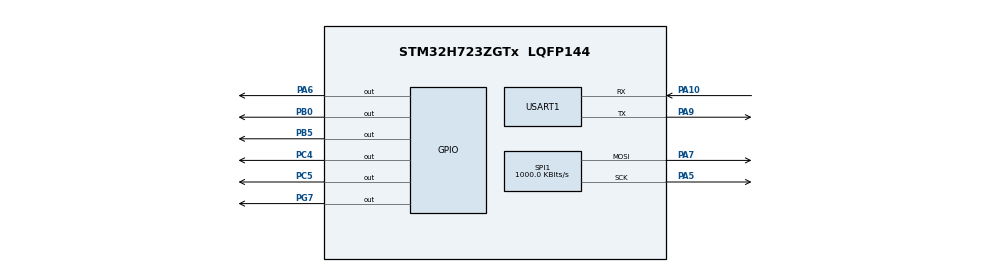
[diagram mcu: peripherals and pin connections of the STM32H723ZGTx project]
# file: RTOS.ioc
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Dma.Request0=SPI1_TX
Dma.SPI1_TX.0.Direction=DMA_MEMORY_TO_PERIPH
Dma.SPI1_TX.0.EventEnable=DISABLE
Dma.SPI1_TX.0.FIFOMode=DMA_FIFOMODE_DISABLE
Dma.SPI1_TX.0.Instance=DMA1_Stream0
Dma.SPI1_TX.0.MemDataAlignment=DMA_MDATAALIGN_BYTE
Dma.SPI1_TX.0.MemInc=DMA_MINC_ENABLE
Dma.SPI1_TX.0.Mode=DMA_NORMAL
Dma.SPI1_TX.0.PeriphDataAlignment=DMA_PDATAALIGN_BYTE
Dma.SPI1_TX.0.PeriphInc=DMA_PINC_DISABLE
Dma.SPI1_TX.0.Polarity=HAL_DMAMUX_REQ_GEN_RISING
Dma.SPI1_TX.0.Priority=DMA_PRIORITY_HIGH
Dma.SPI1_TX.0.RequestNumber=1
Dma.SPI1_TX.0.SignalID=NONE
Dma.SPI1_TX.0.SyncEnable=DISABLE
Dma.SPI1_TX.0.SyncPolarity=HAL_DMAMUX_SYNC_NO_EVENT
Dma.SPI1_TX.0.SyncRequestNumber=1
Dma.SPI1_TX.0.SyncSignalID=NONE
Mcu.Family=STM32H7
Mcu.Name=STM32H723ZGTx
Mcu.Package=LQFP144
NVIC.DMA1_Stream0_IRQn=true\:3\:0\:true\:false\:true\:true\:true\:true
NVIC.PriorityGroup=NVIC_PRIORITYGROUP_4
NVIC.SPI1_IRQn=true\:3\:0\:true\:false\:true\:false\:true\:true
NVIC.TIM7_IRQn=true\:15\:0\:false\:false\:true\:true\:true\:true
NVIC.TimeBase=TIM7_IRQn
NVIC.TimeBaseIP=TIM7
PA10.Mode=Asynchronous
PA10.Signal=USART1_RX
PA13(JTMS/SWDIO).Mode=Serial_Wire
PA13(JTMS/SWDIO).Signal=DEBUG_JTMS-SWDIO
PA14(JTCK/SWCLK).Mode=Serial_Wire
PA14(JTCK/SWCLK).Signal=DEBUG_JTCK-SWCLK
PA5.GPIO_PuPd=GPIO_PULLDOWN
PA5.GPIO_Speed=GPIO_SPEED_FREQ_VERY_HIGH
PA5.Mode=TX_Only_Simplex_Unidirect_Master
PA5.Signal=SPI1_SCK
PA6.GPIO_Speed=GPIO_SPEED_FREQ_HIGH
PA6.PinState=GPIO_PIN_SET
PA6.Signal=GPIO_Output
PA7.GPIO_PuPd=GPIO_PULLUP
PA7.GPIO_Speed=GPIO_SPEED_FREQ_VERY_HIGH
PA7.Mode=TX_Only_Simplex_Unidirect_Master
PA7.Signal=SPI1_MOSI
PA9.Mode=Asynchronous
PA9.Signal=USART1_TX
PB0.GPIO_Speed=GPIO_SPEED_FREQ_HIGH
PB0.PinState=GPIO_PIN_SET
PB0.Signal=GPIO_Output
PB5.GPIO_PuPd=GPIO_PULLUP
PB5.GPIO_Speed=GPIO_SPEED_FREQ_HIGH
PB5.Signal=GPIO_Output
PC14-OSC32_IN.Mode=LSE-External-Oscillator
PC14-OSC32_IN.Signal=RCC_OSC32_IN
PC15-OSC32_OUT.Mode=LSE-External-Oscillator
PC15-OSC32_OUT.Signal=RCC_OSC32_OUT
PC4.GPIO_Speed=GPIO_SPEED_FREQ_HIGH
PC4.Signal=GPIO_Output
PC5.GPIO_Speed=GPIO_SPEED_FREQ_HIGH
PC5.PinState=GPIO_PIN_SET
PC5.Signal=GPIO_Output
PG7.GPIO_PuPd=GPIO_NOPULL
PG7.GPIO_Speed=GPIO_SPEED_FREQ_HIGH
PG7.PinState=GPIO_PIN_SET
PG7.Signal=GPIO_Output
PH0-OSC_IN.Mode=HSE-External-Oscillator
PH0-OSC_IN.Signal=RCC_OSC_IN
PH1-OSC_OUT.Mode=HSE-External-Oscillator
PH1-OSC_OUT.Signal=RCC_OSC_OUT
ProjectManager.HeapSize=0x200
ProjectManager.StackSize=0x400
ProjectManager.TargetToolchain=MDK-ARM V5.32
RCC.ADCFreq_Value=129000000
RCC.APB1Freq_Value=48000000
RCC.APB2Freq_Value=48000000
RCC.APB3Freq_Value=48000000
RCC.APB4Freq_Value=48000000
RCC.CortexFreq_Value=192000000
RCC.D1PPRE=RCC_APB3_DIV2
RCC.D2PPRE1=RCC_APB1_DIV2
RCC.D2PPRE2=RCC_APB2_DIV2
RCC.D3PPRE=RCC_APB4_DIV2
RCC.DIVM1=4
RCC.DIVN1=12
RCC.DIVP1=1
RCC.HCLKFreq_Value=96000000
RCC.HPRE=RCC_HCLK_DIV2
RCC.PLLFRACN=0
RCC.SPI123CLockSelection=RCC_SPI123CLKSOURCE_CLKP
RCC.SYSCLKFreq_VALUE=192000000
RCC.SYSCLKSource=RCC_SYSCLKSOURCE_PLLCLK
RCC.USBFreq_Value=96000000
SPI1.BaudRatePrescaler=SPI_BAUDRATEPRESCALER_64
SPI1.CLKPolarity=SPI_POLARITY_LOW
SPI1.CalculateBaudRate=1000.0 KBits/s
SPI1.DataSize=SPI_DATASIZE_8BIT
SPI1.Direction=SPI_DIRECTION_2LINES_TXONLY
SPI1.MasterKeepIOState=SPI_MASTER_KEEP_IO_STATE_ENABLE
SPI1.Mode=SPI_MODE_MASTER
SPI1.NSSPMode=SPI_NSS_PULSE_DISABLE
SPI1.VirtualType=VM_MASTER
USART1.VirtualMode-Asynchronous=VM_ASYNC
VP_SYS_VS_tim7.Mode=TIM7
board=custom

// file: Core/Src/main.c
/* USER CODE BEGIN Header */
/**
  ******************************************************************************
  * @file           : main.c
  * @brief          : Main program body
  ******************************************************************************
  * @attention
  *
  * Copyright (c) 2024 STMicroelectronics.
  * All rights reserved.
  *
  * This software is licensed under terms that can be found in the LICENSE file
  * in the root directory of this software component.
  * If no LICENSE file comes with this software, it is provided AS-IS.
  *
  ******************************************************************************
  */
/* USER CODE END Header */
#include "main.h"
#include "dma.h"
#include "spi.h"
#include "usart.h"
#include "gpio.h"

/* USER CODE BEGIN Includes */
#include "oledBuff.h"
#include "lcd_init.h"
#include "lcd.h"
#include "pic.h"
/* USER CODE END Includes */

void SystemClock_Config(void);
void PeriphCommonClock_Config(void);

int main(void)
{

  /* MCU Configuration--------------------------------------------------------*/

  /* Reset of all peripherals, Initializes the Flash interface and the Systick. */
  HAL_Init();

  /* Configure the system clock */
  SystemClock_Config();

/* Configure the peripherals common clocks */
  PeriphCommonClock_Config();

  /* Initialize all configured peripherals */
  MX_GPIO_Init();
  MX_DMA_Init();
  MX_SPI1_Init();
  MX_USART1_UART_Init();
  /* USER CODE BEGIN 2 */
  LCD_Init();
  // __HAL_SPI_ENABLE_IT(&hspi1, SPI_IT_TXP);
  LCD_Fill(0,0,240,280,BLACK);
  /* USER CODE END 2 */

  /* Infinite loop */
  while (1)
  {

    /* USER CODE BEGIN 3 */
  // LCD_Fill(0,0,240,280,BLACK);
	// LCD_Fill(0,0,240,280,GREEN);

  LCD_Fill_Buffer(0,0,240,280,GREEN);
	LCD_Refrash();
	LCD_Fill_Buffer(0,0,240,280,BLACK);
	LCD_Refrash();
  }
  /* USER CODE END 3 */
}

void SystemClock_Config(void)
{
  RCC_OscInitTypeDef RCC_OscInitStruct = {0};
  RCC_ClkInitTypeDef RCC_ClkInitStruct = {0};

  /** Supply configuration update enable
  */
  HAL_PWREx_ConfigSupply(PWR_LDO_SUPPLY);

  /** Configure the main internal regulator output voltage
  */
  __HAL_PWR_VOLTAGESCALING_CONFIG(PWR_REGULATOR_VOLTAGE_SCALE2);

  while(!__HAL_PWR_GET_FLAG(PWR_FLAG_VOSRDY)) {}

  /** Initializes the RCC Oscillators according to the specified parameters
  * in the RCC_OscInitTypeDef structure.
  */
  RCC_OscInitStruct.OscillatorType = RCC_OSCILLATORTYPE_HSI;
  RCC_OscInitStruct.HSIState = RCC_HSI_DIV1;
  RCC_OscInitStruct.HSICalibrationValue = 64;
  RCC_OscInitStruct.PLL.PLLState = RCC_PLL_ON;
  RCC_OscInitStruct.PLL.PLLSource = RCC_PLLSOURCE_HSI;
  RCC_OscInitStruct.PLL.PLLM = 4;
  RCC_OscInitStruct.PLL.PLLN = 12;
  RCC_OscInitStruct.PLL.PLLP = 1;
  RCC_OscInitStruct.PLL.PLLQ = 2;
  RCC_OscInitStruct.PLL.PLLR = 2;
  RCC_OscInitStruct.PLL.PLLRGE = RCC_PLL1VCIRANGE_3;
  RCC_OscInitStruct.PLL.PLLVCOSEL = RCC_PLL1VCOWIDE;
  RCC_OscInitStruct.PLL.PLLFRACN = 0;
  if (HAL_RCC_OscConfig(&RCC_OscInitStruct) != HAL_OK)
  {
    Error_Handler();
  }

  /** Initializes the CPU, AHB and APB buses clocks
  */
  RCC_ClkInitStruct.ClockType = RCC_CLOCKTYPE_HCLK|RCC_CLOCKTYPE_SYSCLK
                              |RCC_CLOCKTYPE_PCLK1|RCC_CLOCKTYPE_PCLK2
                              |RCC_CLOCKTYPE_D3PCLK1|RCC_CLOCKTYPE_D1PCLK1;
  RCC_ClkInitStruct.SYSCLKSource = RCC_SYSCLKSOURCE_PLLCLK;
  RCC_ClkInitStruct.SYSCLKDivider = RCC_SYSCLK_DIV1;
  RCC_ClkInitStruct.AHBCLKDivider = RCC_HCLK_DIV2;
  RCC_ClkInitStruct.APB3CLKDivider = RCC_APB3_DIV2;
  RCC_ClkInitStruct.APB1CLKDivider = RCC_APB1_DIV2;
  RCC_ClkInitStruct.APB2CLKDivider = RCC_APB2_DIV2;
  RCC_ClkInitStruct.APB4CLKDivider = RCC_APB4_DIV2;

  if (HAL_RCC_ClockConfig(&RCC_ClkInitStruct, FLASH_LATENCY_1) != HAL_OK)
  {
    Error_Handler();
  }
}

void PeriphCommonClock_Config(void)
{
  RCC_PeriphCLKInitTypeDef PeriphClkInitStruct = {0};

  /** Initializes the peripherals clock
  */
  PeriphClkInitStruct.PeriphClockSelection = RCC_PERIPHCLK_CKPER;
  PeriphClkInitStruct.CkperClockSelection = RCC_CLKPSOURCE_HSI;
  if (HAL_RCCEx_PeriphCLKConfig(&PeriphClkInitStruct) != HAL_OK)
  {
    Error_Handler();
  }
}

void HAL_TIM_PeriodElapsedCallback(TIM_HandleTypeDef *htim)
{
  if (htim->Instance == TIM7) {
    HAL_IncTick();
  }
}

void Error_Handler(void)
{
  __disable_irq();
  while (1)
  {
  }
}
